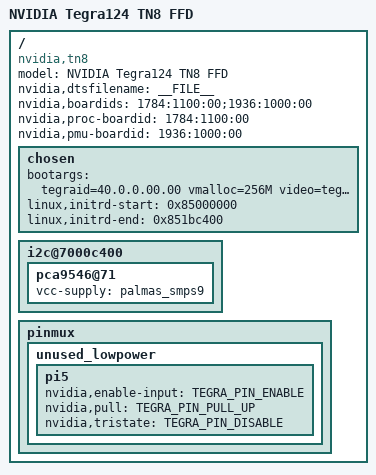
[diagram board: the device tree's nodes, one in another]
/dts-v1/;

/* E1784-1100-A00 + 12x7 + 4GB */

#include "tegra124-tn8.dtsi"
#include "tegra124-platforms/tegra124-tn8-dfll.dtsi"
#include "tegra124-platforms/tegra124-tn8-emc-p1761-1470-a00.dtsi"
#include "tegra124-platforms/tegra124-tn8-powermon-e1784-1101-a00.dtsi"
#include "tegra124-platforms/tegra124-tn8-pmic-e1936-1000-a00.dtsi"
#include "tegra124-platforms/tegra124-tn8-fixed-e1936-1000-a00.dtsi"
#include "tegra124-platforms/tegra124-tn8-sensor-p1761-1470-a00.dtsi"
#include "tegra124-platforms/tegra124-tn8-pinmux-p1761-1470-a00.dtsi"
#include "tegra124-platforms/tegra124-tn8-gpio-p1761-1470-a00.dtsi"
#include "tegra124-platforms/tegra124-tn8-keys-e1780-1100-a02.dtsi"
#include "tegra124-platforms/tegra124-tn8-camera-e1780-a00.dtsi"

/ {
	model = "NVIDIA Tegra124 TN8 FFD";
	compatible = "nvidia,tn8", "nvidia,tegra124";
	nvidia,dtsfilename = __FILE__;
	nvidia,boardids = "1784:1100:00;1936:1000:00";
	nvidia,proc-boardid = "1784:1100:00";
	nvidia,pmu-boardid = "1936:1000:00";
	#address-cells = <2>;
	#size-cells = <2>;

	chosen {
		bootargs = "tegraid=40.0.0.00.00 vmalloc=256M video=tegrafb console=ttyS0,115200n8 earlyprintk";
		linux,initrd-start = <0x85000000>;
		linux,initrd-end = <0x851bc400>;
	};
	i2c@7000c400 {
		pca9546@71 {
			vcc-supply = <&palmas_smps9>;
		};
	};

	pinmux {
		unused_lowpower {
			pi5 {
				nvidia,enable-input = <TEGRA_PIN_ENABLE>;
				nvidia,pull = <TEGRA_PIN_PULL_UP>;
				nvidia,tristate = <TEGRA_PIN_DISABLE>;
			};
		};
	};
};

